VERSION ""

NS_ :

BS_:

BU_: REXCU Vector InstrumentCluster
VAL_TABLE_ vtOnOff 3 "Not available" 2 "Error" 1 "On" 0 "Off" ;
VAL_TABLE_ vAction_t 3 "va_Take_no_action" 2 "va_Reserved" 1 "va_On" 0 "va_Off" ;

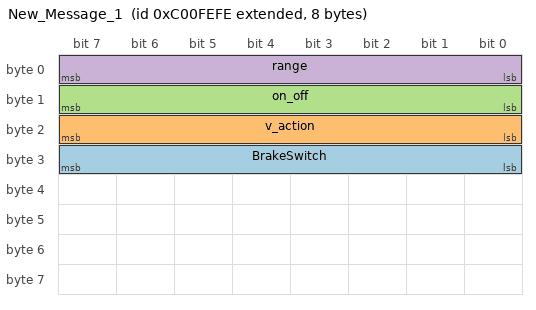
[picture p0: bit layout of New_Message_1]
BO_ 2348875518 New_Message_1: 8 Vector__XXX
 SG_ BrakeSwitch : 24|8@1+ (1,0) [0|0] "" Vector__XXX
 SG_ v_action : 16|8@1+ (1,0) [0|0] "" Vector__XXX
 SG_ on_off : 8|8@1+ (1,0) [0|0] "" Vector__XXX
 SG_ range : 0|8@1+ (1,0) [0|0] "" Vector__XXX

BA_DEF_  "DBName" STRING ;
BA_DEF_ SG_  "SigType" ENUM  "Default","Range","RangeSigned","ASCII","Discrete","Control","ReferencePGN","DTC","StringDelimiter","StringLength","StringLengthControl","MessageCounter","MessageChecksum";
BA_DEF_ SG_  "GenSigSendType" ENUM  "Cyclic","OnWrite","OnWriteWithRepetition","OnChange","OnChangeWithRepetition","IfActive","IfActiveWithRepetition","NoSigSendType";
BA_DEF_ SG_  "GenSigILSupport" ENUM  "No","Yes";
BA_DEF_ SG_  "GenSigEVName" STRING ;
BA_DEF_ BO_  "GenMsgILSupport" ENUM  "No","Yes";
BA_DEF_ BO_  "GenMsgRequestable" INT 0 1;
BA_DEF_ BO_  "GenMsgSendType" ENUM  "cyclic","NotUsed","NotUsed","NotUsed","NotUsed","NotUsed","NotUsed","IfActive","noMsgSendType";
BA_DEF_ BO_  "VFrameFormat" ENUM  "StandardCAN","ExtendedCAN","reserved","J1939PG";
BA_DEF_ BU_  "NmStationAddress" INT 0 255;
BA_DEF_  "SAE_J1939_DA_SpecVersion" STRING ;
BA_DEF_  "SAE_J1939_81_SpecVersion" STRING ;
BA_DEF_  "DatabaseVersion" STRING ;
BA_DEF_  "BusType" STRING ;
BA_DEF_  "ProtocolType" STRING ;
BA_DEF_  "SAE_J1939_75_SpecVersion" STRING ;
BA_DEF_  "SAE_J1939_21_SpecVersion" STRING ;
BA_DEF_  "SAE_J1939_73_SpecVersion" STRING ;
BA_DEF_  "SAE_J1939_71_SpecVersion" STRING ;
BA_DEF_DEF_  "DBName" "";
BA_DEF_DEF_  "SigType" "Default";
BA_DEF_DEF_  "GenSigSendType" "NoSigSendType";
BA_DEF_DEF_  "GenSigILSupport" "Yes";
BA_DEF_DEF_  "GenSigEVName" "Env@Nodename_@Signame";
BA_DEF_DEF_  "GenMsgILSupport" "Yes";
BA_DEF_DEF_  "GenMsgRequestable" 1;
BA_DEF_DEF_  "GenMsgSendType" "noMsgSendType";
BA_DEF_DEF_  "VFrameFormat" "J1939PG";
BA_DEF_DEF_  "NmStationAddress" 254;
BA_DEF_DEF_  "SAE_J1939_DA_SpecVersion" "";
BA_DEF_DEF_  "SAE_J1939_81_SpecVersion" "";
BA_DEF_DEF_  "DatabaseVersion" "";
BA_DEF_DEF_  "BusType" "";
BA_DEF_DEF_  "ProtocolType" "";
BA_DEF_DEF_  "SAE_J1939_75_SpecVersion" "";
BA_DEF_DEF_  "SAE_J1939_21_SpecVersion" "";
BA_DEF_DEF_  "SAE_J1939_73_SpecVersion" "";
BA_DEF_DEF_  "SAE_J1939_71_SpecVersion" "";
BA_ "SAE_J1939_71_SpecVersion" "2012-10";
BA_ "SAE_J1939_73_SpecVersion" "2012-10";
BA_ "SAE_J1939_21_SpecVersion" "2006-10";
BA_ "SAE_J1939_75_SpecVersion" "2012-05";
BA_ "ProtocolType" "J1939";
BA_ "BusType" "CAN";
BA_ "DatabaseVersion" "8.5";
BA_ "SAE_J1939_81_SpecVersion" "2012-05";
BA_ "SAE_J1939_DA_SpecVersion" "2015-01";
BA_ "DBName" "common_enums";
BA_ "NmStationAddress" BU_ REXCU 112;
BA_ "NmStationAddress" BU_ Vector 249;
BA_ "NmStationAddress" BU_ InstrumentCluster 23;
BA_ "SigType" SG_ 2348875518 range 1;
VAL_ 2348875518 BrakeSwitch 3 "Not Available" 2 "Error" 1 "Brake pedal depressed" 0 "Brake pedal released" ;
VAL_ 2348875518 v_action 3 "va_Take_no_action" 2 "va_Reserved" 1 "va_On" 0 "va_Off" ;
VAL_ 2348875518 on_off 3 "Not available" 2 "Error" 1 "On" 0 "Off" ;
